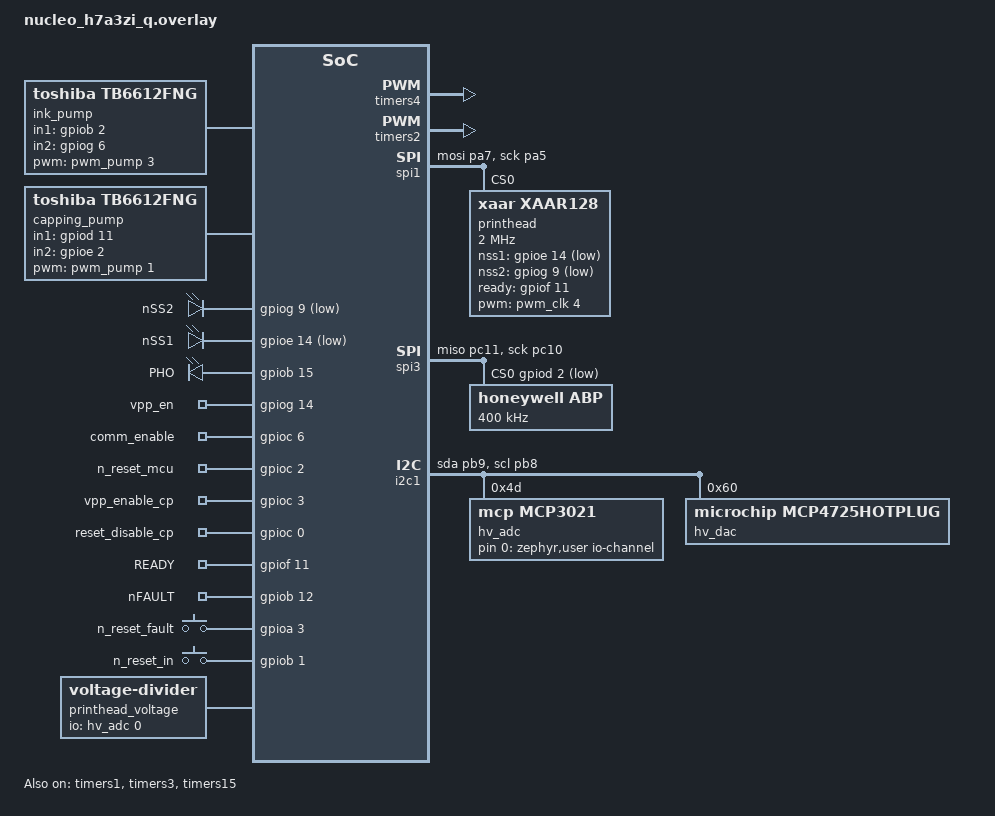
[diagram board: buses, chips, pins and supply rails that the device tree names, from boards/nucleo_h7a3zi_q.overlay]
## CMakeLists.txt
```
#-------------------------------------------------------------------------------
# Zephyr Example Application
#
# Copyright (c) 2021 Nordic Semiconductor ASA
# SPDX-License-Identifier: Apache-2.0

cmake_minimum_required(VERSION 3.13.1)
find_package(Zephyr REQUIRED HINTS $ENV{ZEPHYR_BASE})

project(app LANGUAGES C)

set(PROTOC_OPTIONS "--experimental_allow_proto3_optional")



list(APPEND CMAKE_MODULE_PATH ${ZEPHYR_BASE}/modules/nanopb)
include(nanopb)
zephyr_nanopb_sources(app src/printer_system_state.proto)
zephyr_nanopb_sources(app src/printer_system_state_response.proto)
zephyr_nanopb_sources(app src/printer_request.proto)
zephyr_nanopb_sources(app src/pressure_control.proto)
zephyr_nanopb_sources(app src/print_control.proto)
zephyr_nanopb_sources(app src/waveform_control.proto)

target_sources(app PRIVATE src/main.c)
target_sources(app PRIVATE src/printhead_routines.c)
target_sources(app PRIVATE src/pressure_control.c)
target_sources(app PRIVATE src/pressure_control_algorithm.c)
target_sources(app PRIVATE src/printer_system_smf.c)
target_sources(app PRIVATE src/failure_handling.c)
target_sources(app PRIVATE src/webusb.c)
target_sources(app PRIVATE src/webusb_initialize.c)
target_sources(app PRIVATE src/dropwatcher_light.c)
target_sources(app PRIVATE src/moving_average.c)
target_sources(app PRIVATE src/print_control.c)
target_sources(app PRIVATE src/regulator.c)
include_directories(include)
```

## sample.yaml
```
# This file is provided so that the application can be compiled using Twister,
# the Zephyr testing tool. In this file, multiple combinations can be specified,
# so that you can easily test all of them locally or in CI.
sample:
  description: Inkjet Printer
  name: inkjet-printer
common:
  build_only: true
  integration_platforms:
    - custom_plank
    - nucleo_f302r8
tests:
  app.default: {}
  app.debug:
    extra_overlay_confs:
      - debug.conf
```

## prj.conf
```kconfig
# Copyright (c) 2021 Nordic Semiconductor ASA
# SPDX-License-Identifier: Apache-2.0
#
# This file contains selected Kconfig options for the application.
CONFIG_LOG=y
CONFIG_PRINTER=y
CONFIG_PWM=y
CONFIG_PRINTER_LOG_LEVEL_INF=y
CONFIG_SHELL=y
CONFIG_EVENTS=y
CONFIG_SMF=y
CONFIG_SENSOR=y
CONFIG_MOTOR=y
CONFIG_ADC=y
CONFIG_DAC=y
CONFIG_CBPRINTF_FP_SUPPORT=y
CONFIG_INKJETCONTROL=y
CONFIG_INKJETCONTROL_LOG_LEVEL_INF=y


CONFIG_USB_DEVICE_STACK=y
CONFIG_USB_DEVICE_BOS=y
CONFIG_USB_DEVICE_PRODUCT="Zephyr WebUSB sample"
CONFIG_USB_DEVICE_PID=0x000A
CONFIG_USB_DEVICE_VID=0x2FE3
CONFIG_USB_DEVICE_INITIALIZE_AT_BOOT=n
# CONFIG_USB_DEVICE_LOG_LEVEL_DBG=y

CONFIG_NANOPB=y

CONFIG_SYSTEM_WORKQUEUE_STACK_SIZE=2048
```

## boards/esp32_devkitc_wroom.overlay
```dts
/ {

    ink_pump: ink_pump {
		status = "okay";
		compatible = "toshiba,tb6612fng";
		pwms = <&mcpwm0 0 PWM_HZ(1000) PWM_POLARITY_NORMAL>;
		in1-gpios = <&gpio0 23 GPIO_ACTIVE_HIGH>;
		in2-gpios = <&gpio0 22 GPIO_ACTIVE_HIGH>;
	};
};


&spi2 {
    status = "okay";
    abp: abp@0 {
		status = "okay";
		compatible = "honeywell,abp";
		reg = <0>;
		spi-max-frequency = <400000>;
	};
};

 &pinctrl {
    mcpwm0_default: mcpwm0_default {
      group1 {
        pinmux = <MCPWM0_OUT0A_GPIO2>;
        output-enable;
      };
    };
  };

&mcpwm0 {
    status = "okay";
    prescale = <255>;
    prescale-timer0 = <1>;
    pinctrl-0 = <&mcpwm0_default>;
    pinctrl-names = "default";
};
```

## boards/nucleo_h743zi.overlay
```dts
#define PRINTHEAD_CLOCK_NS PWM_HZ(1000000)
#define MAX_FIRE_FREQUENCY PWM_HZ(4000)

/ {

	pwmclock: pwmclock1 {
		status = "okay";
		compatible = "pwm-clock";
		#clock-cells = <1>;
		pwms = <&pwm_clk 4 PRINTHEAD_CLOCK_NS PWM_POLARITY_INVERTED>;
	};

    ink_pump: ink_pump {
		status = "okay";
		compatible = "toshiba,tb6612fng";
		pwms = <&pwm_pump 3 PWM_HZ(1000) PWM_POLARITY_NORMAL>;
		in1-gpios = <&gpiob 2 GPIO_ACTIVE_HIGH>;
		in2-gpios = <&gpiog 6 GPIO_ACTIVE_HIGH>;
	};

	controlpins: controlpins {
		compatible = "gpio-leds";
		nSS2: nSS2 { //these will be handled in the printhead driver
			gpios = <&gpiog 9 GPIO_ACTIVE_LOW>;
		};
		nSS1: nSS1 {
			gpios = <&gpioe 14 GPIO_ACTIVE_LOW>;
		};
		PHO: PHO {
			gpios = <&gpiob 15 GPIO_ACTIVE_HIGH>;
		};

		//outputs
		vpp_en: vpp_en {
			gpios = <&gpiog 14 GPIO_ACTIVE_HIGH>;
		};
		comm_enable: comm_enable {
			gpios = <&gpioc 6 GPIO_ACTIVE_HIGH>;
		};
		n_reset_mcu: n_reset_mcu {
			gpios = <&gpioc 2 GPIO_ACTIVE_HIGH>;
		};
		vpp_enable_cp: vpp_enable_cp {
			gpios = <&gpioc 3 GPIO_ACTIVE_HIGH>;
		};
		reset_disable_cp: reset_disable_cp {
			gpios = <&gpioc 0 GPIO_ACTIVE_HIGH>;
		};
	};

	monitorpins: monitorpins {
		compatible = "gpio-keys";

		READY: READY {
			gpios = <&gpiof 11 GPIO_ACTIVE_HIGH>;
		};
		nFAULT: nFAULT {
			gpios = <&gpiob 12 GPIO_ACTIVE_HIGH>;
		};

		//inputs
		n_reset_fault: n_reset_fault {
			gpios = <&gpioa 3 GPIO_ACTIVE_HIGH>;
		};
		n_reset_in: n_reset_in {
			gpios = <&gpiob 1 GPIO_ACTIVE_HIGH>;
		};
	};
};


&pll {
	div-m = <1>;
	mul-n = <24>;
	div-p = <2>;
	div-q = <2>;
	div-r = <2>;
	clocks = <&clk_hse>;
	status = "okay";
};

&rcc {
	clocks = <&pll>;
	clock-frequency = <DT_FREQ_M(96)>;
	d1cpre = <1>;
	hpre = <1>;
	d1ppre = <1>;
	d2ppre1 = <2>;
	d2ppre2 = <1>;
	d3ppre = <1>;
};

&timers4 {
	st,prescaler = <0>;

	status = "okay";
	pwm_clk: pwm {
		status = "okay";
		pinctrl-names = "default";
		pinctrl-0 = <&tim4_ch4_pd15>;
	};
};

&timers2 {
	status = "okay";
	st,prescaler = <64>;

	pwm_pump: pwm {
		status = "okay";
		pinctrl-names = "default";
		pinctrl-0 = <&tim2_ch3_pa2>;
	};	
};

&timers1 {
	st,prescaler = <0>;
	status = "okay";

	printer_fire: printer_fire {
		compatible = "st,fire-stm32-combined-pwm";
		status = "okay";
		pinctrl-names = "default";
		pinctrl-0 = <&tim1_ch2_pe11 &tim1_ch3_pe13>;
		pulse12_start = <(PRINTHEAD_CLOCK_NS/4)>;
		pulse34_start = <(PRINTHEAD_CLOCK_NS/4)>;
		pulse12_end = <((PRINTHEAD_CLOCK_NS/4) + PRINTHEAD_CLOCK_NS)>;
		pulse34_end = <(2*PRINTHEAD_CLOCK_NS)>;
		mask_period = <MAX_FIRE_FREQUENCY>;
	};
};

&spi1 {
	status = "okay";
	pinctrl-names = "default";
	pinctrl-0 = <&spi1_mosi_pa7 &spi1_sck_pa5>;
	printhead: printhead@0 {
		compatible = "xaar,xaar128";
		clocks = <&pwmclock 0>;
		reg = <0>;
		spi-max-frequency = <1000000>;
		nss1-gpios = <&gpioe 14 GPIO_ACTIVE_LOW>;
		nss2-gpios = <&gpiog 9 GPIO_ACTIVE_LOW>;
	};
};

&spi3 {
	status = "okay";
	pinctrl-names = "default";
	pinctrl-0 = <&spi3_miso_pc11 &spi3_sck_pc10>;
	cs-gpios = <&gpiod 2 GPIO_ACTIVE_LOW>;
	abp: abp@0 {
		status = "okay";
		compatible = "honeywell,abp";
		reg = <0>;
		spi-max-frequency = <400000>;
	};
};
```

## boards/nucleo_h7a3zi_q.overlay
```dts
#define PRINTHEAD_CLOCK_NS PWM_HZ(1000000)
#define MAX_FIRE_FREQUENCY PWM_HZ(4250)

/ {
	zephyr,user {
		io-channels =  <&hv_adc 0>;
	};

    ink_pump: ink_pump {
		status = "okay";
		compatible = "toshiba,tb6612fng";
		pwms = <&pwm_pump 3 PWM_HZ(1000) PWM_POLARITY_NORMAL>;
		in1-gpios = <&gpiob 2 GPIO_ACTIVE_HIGH>;
		in2-gpios = <&gpiog 6 GPIO_ACTIVE_HIGH>;
	};

	capping_pump: capping_pump {
		status = "okay";
		compatible = "toshiba,tb6612fng";
		pwms = <&pwm_pump 1 PWM_HZ(1000) PWM_POLARITY_NORMAL>;
		in1-gpios = <&gpiod 11 GPIO_ACTIVE_HIGH>;
		in2-gpios = <&gpioe 2 GPIO_ACTIVE_HIGH>;
	};

	controlpins: controlpins {
		compatible = "gpio-leds";
		nSS2: nSS2 { //these will be handled in the printhead driver
			gpios = <&gpiog 9 GPIO_ACTIVE_LOW>;
		};
		nSS1: nSS1 {
			gpios = <&gpioe 14 GPIO_ACTIVE_LOW>;
		};
		PHO: PHO {
			gpios = <&gpiob 15 GPIO_ACTIVE_HIGH>;
		};

		//outputs
		vpp_en: vpp_en {
			gpios = <&gpiog 14 GPIO_ACTIVE_HIGH>;
		};
		comm_enable: comm_enable {
			gpios = <&gpioc 6 GPIO_ACTIVE_HIGH>;
		};
		n_reset_mcu: n_reset_mcu {
			gpios = <&gpioc 2 GPIO_ACTIVE_HIGH>;
		};
		vpp_enable_cp: vpp_enable_cp {
			gpios = <&gpioc 3 GPIO_ACTIVE_HIGH>;
		};
		reset_disable_cp: reset_disable_cp {
			gpios = <&gpioc 0 GPIO_ACTIVE_HIGH>;
		};
	};

	monitorpins: monitorpins {
		compatible = "gpio-keys";

		READY: READY {
			gpios = <&gpiof 11 GPIO_ACTIVE_HIGH>;
		};
		nFAULT: nFAULT {
			gpios = <&gpiob 12 GPIO_ACTIVE_HIGH>;
		};

		//inputs
		n_reset_fault: n_reset_fault {
			gpios = <&gpioa 3 GPIO_ACTIVE_HIGH>;
		};
		n_reset_in: n_reset_in {
			gpios = <&gpiob 1 GPIO_ACTIVE_HIGH>;
		};
	};

    printhead_voltage: printhead_voltage {
    	compatible = "voltage-divider";
    	io-channels = <&hv_adc 0>;
    	output-ohms = <12000>;
    	full-ohms = <(100000 + 12000)>;
    };
};


&pll {
	div-m = <1>;
	mul-n = <24>;
	div-p = <2>;
	div-q = <2>;
	div-r = <2>;
	clocks = <&clk_hse>;
	status = "okay";
};

&rcc {
	clocks = <&pll>;
	clock-frequency = <DT_FREQ_M(96)>;
	d1cpre = <1>;
	hpre = <1>;
	d1ppre = <1>;
	d2ppre1 = <2>;
	d2ppre2 = <1>;
	d3ppre = <1>;
};

&timers4 {
	st,prescaler = <0>;

	status = "okay";
	pwm_clk: pwm {
		status = "okay";
		pinctrl-names = "default";
		pinctrl-0 = <&tim4_ch4_pd15>;
	};
};

&timers2 {
	status = "okay";
	st,prescaler = <64>;

	pwm_pump: pwm {
		status = "okay";
		pinctrl-names = "default";
		pinctrl-0 = <&tim2_ch3_pa2 &tim2_ch1_pa0>;
	};	
};

&timers1 {
	st,prescaler = <0>;
	status = "okay";

	interrupts = <24 1>, <25 1>, <26 0>, <27 1>;

	printer_fire: printer_fire {
		compatible = "st,fire-stm32-combined-pwm";
		status = "okay";
		pinctrl-names = "default";
		pinctrl-0 = <&tim1_ch2_pe11 &tim1_ch3_pe13>;
		pulse12_start = <(PRINTHEAD_CLOCK_NS/4)>;
		pulse34_start = <(PRINTHEAD_CLOCK_NS/4)>;
		pulse12_end = <((PRINTHEAD_CLOCK_NS/4) + PRINTHEAD_CLOCK_NS)>;
		pulse34_end = <(2*PRINTHEAD_CLOCK_NS)>;
		min_mask_period = <MAX_FIRE_FREQUENCY>;
		#printer-fire-cells = <0>;
		encoder_timer = <&timers3>;
		clock_timer = <&timers4>;
		encoder_timer_trigger = <0>; // ITR0 -> timer15
		clock_timer_trigger = <((1<<4)|(2<<4))>; // ITR3 -> timer4
	};
};

&timers3 {
	st,prescaler = <0>; // apb 1
	status = "okay";

	interrupts = <29 1>;

	qdec: qdec {
		compatible = "st,stm32-qdec-linear";
		status = "okay";
		pinctrl-0 = <&tim3_ch1_pb4 &tim3_ch2_pc7>;
		pinctrl-names = "default";
		st,input-polarity-inverted;
		st,input-filter-level = <15>; // f/32, n=8
		st,encoder-mode = <3>;
		encoder-xor-timer = <&timers15>;
		encoder-xor-timer-remap = <((2<<0)|(2<<8))>; // LL_TIM_TIM15_TI1_RMP_TIM3_CH1 | LL_TIM_TIM15_TI2_RMP_TIM3_CH2
	};
};

&timers15 {
	st,prescaler = <0>;
	status = "okay";
};

&spi1 {
	status = "okay";
	pinctrl-names = "default";
	pinctrl-0 = <&spi1_mosi_pa7 &spi1_sck_pa5>;
	printhead: printhead@0 {
		compatible = "xaar,xaar128";
		pwms= <&pwm_clk 4 PRINTHEAD_CLOCK_NS PWM_POLARITY_INVERTED>;
		reg = <0>;
		spi-max-frequency = <2000000>;
		nss1-gpios = <&gpioe 14 GPIO_ACTIVE_LOW>;
		nss2-gpios = <&gpiog 9 GPIO_ACTIVE_LOW>;
		ready-gpios = <&gpiof 11 GPIO_ACTIVE_HIGH>;
		printer-fires = <&printer_fire>;
	};
};

&spi3 {
	status = "okay";
	pinctrl-names = "default";
	pinctrl-0 = <&spi3_miso_pc11 &spi3_sck_pc10>;
	cs-gpios = <&gpiod 2 GPIO_ACTIVE_LOW>;
	abp: abp@0 {
		status = "okay";
		compatible = "honeywell,abp";
		reg = <0>;
		spi-max-frequency = <400000>;
	};
};

&usart3 {
	interrupts = <39 1>;
};

&usbotg_hs {
	interrupts = <77 1>, <74 1>, <75 1>;
};

&exti {
	interrupts = <6 1>, <7 1>, <8 1>, <9 1>,
				     <10 1>, <23 1>, <40 1>;
};

&i2c1 {
	status = "okay";
	pinctrl-names = "default";
	pinctrl-0 = <&i2c1_sda_pb9 &i2c1_scl_pb8>;
	hv_adc: adc@4d {
		status = "okay";
		compatible = "mcp,mcp3021";

		#io-channel-cells = <1>;
		#address-cells = <1>;
		#size-cells = <0>;
		
		
		reg = <0x4d>;

		ref-internal-mv = <5000>;

		channel@0 {
			reg = <0>;
			zephyr,gain = "ADC_GAIN_1";
			zephyr,reference = "ADC_REF_INTERNAL";
			zephyr,acquisition-time = <ADC_ACQ_TIME_DEFAULT>;
			zephyr,resolution = <10>;
		};
	};

	hv_dac: dac@60 {
		status = "okay";
		compatible = "microchip,mcp4725hotplug";
		
		#io-channel-cells = <1>;
		#address-cells = <1>;
		#size-cells = <0>;

		reg = <0x60>;

	};
};
```

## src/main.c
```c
#include <zephyr/kernel.h>
#include <zephyr/drivers/printer.h>
#include <zephyr/drivers/printer_fire.h>
#include <app_version.h>
#include <zephyr/kernel.h>
#include <zephyr/device.h>
#include <zephyr/drivers/gpio.h>
#include <zephyr/sys/util.h>
#include <zephyr/sys/printk.h>
#include <inttypes.h>
#include <zephyr/logging/log.h>
#include <zephyr/shell/shell.h>
#include <zephyr/console/console.h>
#include <stdlib.h>
#include <zephyr/drivers/sensor.h>
#include <zephyr/drivers/motor.h>
#include <zephyr/drivers/pwm.h>

#include "pressure_control.h"
#include "printhead_routines.h"
#include "printer_system_smf.h"
#include "failure_handling.h"
#include "print_control.h"
#include "regulator.h"

LOG_MODULE_REGISTER(main, CONFIG_APP_LOG_LEVEL);
#define SW0_NODE DT_ALIAS(sw0)
#if !DT_NODE_HAS_STATUS(SW0_NODE, okay)
#error "Unsupported board: sw0 devicetree alias is not defined"
#endif

static const struct gpio_dt_spec button = GPIO_DT_SPEC_GET_OR(SW0_NODE, gpios,
															  {0});
static struct gpio_callback button_cb_data;

static const struct gpio_dt_spec vpp_en = GPIO_DT_SPEC_GET(DT_NODELABEL(vpp_en), gpios);
static const struct gpio_dt_spec comm_enable = GPIO_DT_SPEC_GET(DT_NODELABEL(comm_enable), gpios);
static const struct gpio_dt_spec vpp_enable_cp = GPIO_DT_SPEC_GET(DT_NODELABEL(vpp_enable_cp), gpios);

static const struct gpio_dt_spec n_reset_fault = GPIO_DT_SPEC_GET(DT_NODELABEL(n_reset_fault), gpios);
static const struct gpio_dt_spec n_reset_in = GPIO_DT_SPEC_GET(DT_NODELABEL(n_reset_in), gpios);

static struct gpio_dt_spec nSS2 = GPIO_DT_SPEC_GET(DT_NODELABEL(nss2), gpios);
static struct gpio_dt_spec nSS1 = GPIO_DT_SPEC_GET(DT_NODELABEL(nss1), gpios);
static struct gpio_dt_spec PHO = GPIO_DT_SPEC_GET(DT_NODELABEL(pho), gpios);

static struct gpio_dt_spec nFAULT = GPIO_DT_SPEC_GET(DT_NODELABEL(nfault), gpios);
static struct gpio_dt_spec READY = GPIO_DT_SPEC_GET(DT_NODELABEL(ready), gpios);

static struct gpio_callback READY_cb_data;

void encoder_debug_timer_handler(struct k_timer *timer)
{
	const struct device *const dev = DEVICE_DT_GET(DT_NODELABEL(qdec));
	if (!device_is_ready(dev))
	{
		printk("Qdec device is not ready\n");
		return;
	}
	struct sensor_value val;
	int rc = sensor_sample_fetch(dev);
	rc = sensor_channel_get(dev, SENSOR_CHAN_POS_DX, &val);
	if (rc != 0)
	{
		printk("Failed to get data (%d)\n", rc);
		return;
	}
	printk("Encoder value: %d\n", val.val1);
}

void pressure_debug_timer_handler(struct k_timer *timer)
{
	double pressure = pressure_control_get_pressure();
	printk("Pressure: %f mbar\n", pressure);
}
static int fire_count = 0;
static int drop_count = 100;

void print_fire_timer_handler(struct k_timer *timer);

K_TIMER_DEFINE(pressure_debug_timer, pressure_debug_timer_handler, NULL);

K_TIMER_DEFINE(print_fire_timer, print_fire_timer_handler, NULL);

K_TIMER_DEFINE(encoder_debug_timer, encoder_debug_timer_handler, NULL);

static uint32_t pattern[4] = {0, 0, 0, 1};

static void advance_pattern()
{
	bool filling = (pattern[3] & 0x80000000) == 0;
	for (int i = 3; i >= 0; i--)
	{
		pattern[i] = (pattern[i] << 1);
		if (i > 0 && (pattern[i - 1] & 0x80000000))
		{
			pattern[i] |= 1;
		}
	}
	if (pattern[3] & 0x80000000)
	{
		pattern[0] |= 1;
	}
	// if (filling)
	// {
	// 	pattern[0] |= 1;
	// }
}

void print_fire_timer_handler(struct k_timer *timer)
{
	if (gpio_pin_get_dt(&READY) == 1)
	{
		// if (fire_count % 30 == 0)
		// {
		// 	advance_pattern();
		// }
		const struct device *printhead = DEVICE_DT_GET(DT_NODELABEL(printhead));
		// printer_set_pixels(printhead, pattern);
		request_printhead_fire();
	}
	fire_count++;
	if (fire_count > drop_count)
	{
		k_timer_stop(&print_fire_timer);
		fire_count = 0;
	}
}

K_EVENT_DEFINE(btn_event);

void button_pressed(const struct device *dev, struct gpio_callback *cb,
					uint32_t pins)
{
	failure_handling_set_error_state(ERROR_USER_ABORT);
}

void READY_int_handler(const struct device *dev, struct gpio_callback *cb,
					   uint32_t pins)
{
	LOG_INF("READY changed to %d", gpio_pin_get_dt(&READY));
}

static int printhead_io_init()
{
	int ret;
	if (!gpio_is_ready_dt(&nSS2))
	{
		LOG_ERR("Error: nSS2 device %s is not ready\n",
				nSS2.port->name);
		return ENODEV;
	}
	ret = gpio_pin_configure_dt(&nSS2, GPIO_OUTPUT_INACTIVE);
	if (ret != 0)
	{
		LOG_ERR("Error %d: failed to configure %s pin %d\n",
				ret, nSS2.port->name, nSS2.pin);
		return ret;
	}
	if (!gpio_is_ready_dt(&nSS1))
	{
		LOG_ERR("Error: nSS1 device %s is not ready\n",
				nSS1.port->name);
		return ENODEV;
	}
	ret = gpio_pin_configure_dt(&nSS1, GPIO_OUTPUT_INACTIVE);
	if (ret != 0)
	{
		LOG_ERR("Error %d: failed to configure %s pin %d\n",
				ret, nSS1.port->name, nSS1.pin);
		return ret;
	}
	if (!gpio_is_ready_dt(&PHO))
	{
		LOG_ERR("Error: PHO device %s is not ready\n",
				PHO.port->name);
		return ENODEV;
	}
	ret = gpio_pin_configure_dt(&PHO, GPIO_OUTPUT_INACTIVE);
	if (ret != 0)
	{
		LOG_ERR("Error %d: failed to configure %s pin %d\n",
				ret, PHO.port->name, PHO.pin);
		return ret;
	}
	if (!gpio_is_ready_dt(&READY))
	{
		LOG_ERR("Error: READY device %s is not ready\n",
				READY.port->name);
		return ENODEV;
	}
	ret = gpio_pin_configure_dt(&READY, GPIO_INPUT);
	if (ret != 0)
	{
		LOG_ERR("Error %d: failed to configure %s pin %d\n",
				ret, READY.port->name, READY.pin);
		return ret;
	}
	ret = gpio_pin_interrupt_configure_dt(&READY,
										  GPIO_INT_EDGE_BOTH);
	if (ret != 0)
	{
		LOG_ERR("Error %d: failed to configure interrupt on %s pin %d\n",
				ret, READY.port->name, READY.pin);
		return ret;
	}
	gpio_init_callback(&READY_cb_data, READY_int_handler, BIT(READY.pin));
	ret = gpio_add_callback(READY.port, &READY_cb_data);
	if (ret != 0)
	{
		LOG_ERR("Error %d: failed to add callback on %s pin %d\n",
				ret, READY.port->name, READY.pin);
		return ret;
	}
	return 0;
}

int initialize_io()
{
	int ret;
	ret = printhead_io_init();
	if (ret != 0)
	{
		return ret;
	}
	return 0;
}

static int shell_wait(const struct shell *sh)
{
	int32_t events;
	shell_print(sh, "Press button to continue.");
	k_event_clear(&btn_event, 0x1);
	events = k_event_wait_all(&btn_event, 0x1, false, K_SECONDS(20));
	if (events == 0)
	{
		shell_print(sh, "Timeout");
		return ETIMEDOUT;
	}
	return 0;
}

static int cmd_test_hv_supply(const struct shell *sh, size_t argc, char **argv)
{
	ARG_UNUSED(argc);
	ARG_UNUSED(argv);

	shell_print(sh, "Disconnect HV supply, discharge capacitor, confirm 0V on printhead connector VPPH and VPPL.");
	if (shell_wait(sh) == ETIMEDOUT)
	{
		return ETIMEDOUT;
	}
	shell_print(sh, "Connect HV supply, confirm 0V on printhead connector VPPH and VPPL.");
	if (shell_wait(sh) == ETIMEDOUT)
	{
		return ETIMEDOUT;
	}
	gpio_pin_set_dt(&vpp_en, 1);
	shell_print(sh, "Confirm again 0V on VPPH and VPPL.");
	if (shell_wait(sh) == ETIMEDOUT)
	{
		return ETIMEDOUT;
	}
	gpio_pin_set_dt(&vpp_enable_cp, 1);
	k_sleep(K_MSEC(1));
	gpio_pin_set_dt(&vpp_enable_cp, 0);
	shell_print(sh, "Confirm VPPH and VPPL active.");
	if (shell_wait(sh) == ETIMEDOUT)
	{
		return ETIMEDOUT;
	}
	gpio_pin_set_dt(&vpp_en, 0);
	shell_print(sh, "Confirm again 0V on VPPH and VPPL.");
	if (shell_wait(sh) == ETIMEDOUT)
	{
		return ETIMEDOUT;
	}
	shell_print(sh, "done");
	return 0;
}

static int cmd_test_printhead_io(const struct shell *sh, size_t argc, char **argv)
{
	ARG_UNUSED(argc);
	ARG_UNUSED(argv);

	gpio_pin_set_dt(&nSS2, 1);
	gpio_pin_set_dt(&nSS1, 1);
	gpio_pin_set_dt(&PHO, 0);
	gpio_pin_set_dt(&comm_enable, 1);
	shell_print(sh, "Connect nSS2 to READY");
	if (shell_wait(sh) == ETIMEDOUT)
	{
		return ETIMEDOUT;
	}
	if (gpio_pin_get_dt(&READY) != 0)
	{
		shell_print(sh, "READY is not low");
		return EINVAL;
	}
	gpio_pin_set_dt(&nSS2, 0);
	k_sleep(K_MSEC(1));
	if (gpio_pin_get_dt(&READY) != 1)
	{
		shell_print(sh, "READY is not high");
		return EINVAL;
	}
	gpio_pin_set_dt(&nSS2, 1);
	shell_print(sh, "Connect nSS1 to READY");
	if (shell_wait(sh) == ETIMEDOUT)
	{
		return ETIMEDOUT;
	}
	if (gpio_pin_get_dt(&READY) != 0)
	{
		shell_print(sh, "READY is not low");
		return EINVAL;
	}
	gpio_pin_set_dt(&nSS1, 0);
	k_sleep(K_MSEC(1));
	if (gpio_pin_get_dt(&READY) != 1)
	{
		shell_print(sh, "READY is not high");
		return EINVAL;
	}
	gpio_pin_set_dt(&nSS1, 1);
	shell_print(sh, "Connect PHO to nFAULT");
	if (shell_wait(sh) == ETIMEDOUT)
	{
		return ETIMEDOUT;
	}
	if (gpio_pin_get_dt(&nFAULT) != 0)
	{
		shell_print(sh, "nFAULT is not low");
		return EINVAL;
	}
	gpio_pin_set_dt(&PHO, 1);
	k_sleep(K_MSEC(1));
	if (gpio_pin_get_dt(&nFAULT) != 1)
	{
		shell_print(sh, "nFAULT is not high");
		return EINVAL;
	}
	gpio_pin_set_dt(&PHO, 0);
	shell_print(sh, "done");
	return 0;
}

static int cmd_test_other_io(const struct shell *sh, size_t argc, char **argv)
{
	ARG_UNUSED(argc);
	ARG_UNUSED(argv);
	gpio_pin_set_dt(&comm_enable, 0);
	shell_print(sh, "Connect COMM_ENABLE to nRESET_FAULT");
	if (shell_wait(sh) == ETIMEDOUT)
	{
		return ETIMEDOUT;
	}
	if (gpio_pin_get_dt(&n_reset_fault) != 0)
	{
		shell_print(sh, "nRESET_FAULT is not low");
		return EINVAL;
	}
	gpio_pin_set_dt(&comm_enable, 1);
	k_sleep(K_MSEC(1));
	if (gpio_pin_get_dt(&n_reset_fault) != 1)
	{
		shell_print(sh, "nRESET_FAULT is not high");
		return EINVAL;
	}
	gpio_pin_set_dt(&comm_enable, 0);
	shell_print(sh, "Connect COMM_ENABLE to nRESET_IN");
	if (shell_wait(sh) == ETIMEDOUT)
	{
		return ETIMEDOUT;
	}
	if (gpio_pin_get_dt(&n_reset_in) != 0)
	{
		shell_print(sh, "nRESET_IN is not low");
		return EINVAL;
	}
	gpio_pin_set_dt(&comm_enable, 1);
	k_sleep(K_MSEC(1));
	if (gpio_pin_get_dt(&n_reset_in) != 1)
	{
		shell_print(sh, "nRESET_IN is not high");
		return EINVAL;
	}
	gpio_pin_set_dt(&comm_enable, 0);
	shell_print(sh, "done");
	return 0;
}

static int cmd_set_pixels(const struct shell *sh, size_t argc, char **argv)
{
	if (argc != 5)
	{
		shell_print(sh, "Usage: set_pixels <pixels1> <pixels2> <pixels3> <pixels4>");
		return EINVAL;
	}
	uint32_t pixels[4] = {(uint32_t)strtoll(argv[1], NULL, 16), (uint32_t)strtoll(argv[2], NULL, 16), (uint32_t)strtoll(argv[3], NULL, 16), (uint32_t)strtoll(argv[4], NULL, 16)};
	shell_print(sh, "Setting pixels to %d %d %d %d", pixels[0], pixels[1], pixels[2], pixels[3]);
	k_sleep(K_SECONDS(1));
	const struct device *printhead;
	printhead = DEVICE_DT_GET(DT_NODELABEL(printhead));

	return printer_set_pixels(printhead, pixels);
}

static int cmd_comm_enable(const struct shell *sh, size_t argc, char **argv)
{
	if (argc != 2)
	{
		shell_print(sh, "Usage: comm_enable <0|1>");
		return EINVAL;
	}
	int value = atoi(argv[1]);
	if (value != 0 && value != 1)
	{
		shell_print(sh, "Usage: comm_enable <0|1>");
		return EINVAL;
	}
	gpio_pin_set_dt(&comm_enable, value);
	return 0;
}

static int cmd_pressure_control_enable(const struct shell *sh, size_t argc, char **argv, void *data)
{
	ARG_UNUSED(argc);
	ARG_UNUSED(argv);
	bool enable = (bool)data;
	if (enable)
	{
		pressure_control_enable();
	}
	else
	{
		pressure_control_disable();
	}
	return 0;
}

SHELL_SUBCMD_DICT_SET_CREATE(pressure_control_enable_cmds, cmd_pressure_control_enable,
							 (enable, true, "enable"), (disable, false, "disable"));

static int cmd_pressure_control_print_pressure(const struct shell *sh, size_t argc, char **argv, void *data)
{
	ARG_UNUSED(argc);
	ARG_UNUSED(argv);
	bool enable = (bool)data;
	if (enable)
	{
		k_timer_start(&pressure_debug_timer, K_SECONDS(1), K_SECONDS(1));
	}
	else
	{
		k_timer_stop(&pressure_debug_timer);
	}
	return 0;
}

SHELL_SUBCMD_DICT_SET_CREATE(pressure_control_print_pressure_cmds, cmd_pressure_control_print_pressure,
							 (enable, true, "enable"), (disable, false, "disable"));

static int cmd_encoder_print(const struct shell *sh, size_t argc, char **argv, void *data)
{
	ARG_UNUSED(argc);
	ARG_UNUSED(argv);
	bool enable = (bool)data;
	if (enable)
	{
		k_timer_start(&encoder_debug_timer, K_SECONDS(1), K_SECONDS(1));
	}
	else
	{
		k_timer_stop(&encoder_debug_timer);
	}
	return 0;
}

SHELL_SUBCMD_DICT_SET_CREATE(encoder_print_cmds, cmd_encoder_print,
							 (enable, true, "enable"), (disable, false, "disable"));

static int cmd_pressure_control_calibrate_zero_pressure(const struct shell *sh, size_t argc, char **argv)
{
	ARG_UNUSED(argc);
	ARG_UNUSED(argv);
	return calibrate_zero_pressure();
}

static int cmd_test_pump(const struct shell *sh, size_t argc, char **argv)
{
	ARG_UNUSED(argc);
	ARG_UNUSED(argv);
	if (argc != 4)
	{
		goto print_pump_usage;
	}
	const struct device *pump;
	char *pump_name_capping = "capping";
	char *pump_name_ink = "ink";
	char *pump_name;
	if (strcmp(argv[1], "ink") == 0)
	{
		pump = DEVICE_DT_GET(DT_NODELABEL(ink_pump));
		pump_name = pump_name_ink;
	}
	else if (strcmp(argv[1], "capping") == 0)
	{
		pump = DEVICE_DT_GET(DT_NODELABEL(capping_pump));
		pump_name = pump_name_capping;
	}
	else
	{
		goto print_pump_usage;
	}
	motor_action_t action;
	if (strcmp(argv[2], "cw") == 0)
	{
		action = MOTOR_ACTION_CW;
	}
	else if (strcmp(argv[2], "ccw") == 0)
	{
		action = MOTOR_ACTION_CCW;
	}
	else if (strcmp(argv[2], "brake") == 0)
	{
		action = MOTOR_ACTION_SHORT_BRAKE;
	}
	else if (strcmp(argv[2], "stop") == 0)
	{
		action = MOTOR_ACTION_STOP;
	}
	else
	{
		goto print_pump_usage;
	}
	float speed = atof(argv[3]);
	if (!device_is_ready(pump))
	{
		LOG_ERR("Pump not ready");
		return -ENODEV;
	}
	shell_print(sh, "Setting pump %s to %d at %f", pump_name, action, (double)speed);
	motor_set_action(pump, action, speed);
	return 0;
print_pump_usage:
	shell_print(sh, "Usage: test_pump <ink|capping> <cw|ccw|brake|stop> <pwm>");
	return -EINVAL;
}

static int cmd_system_state(const struct shell *sh, size_t argc, char **argv, void *data)
{
	switch ((int)data)
	{
	case 0:
		k_timer_stop(&print_fire_timer);
		go_to_idle();
		break;
	case 1:
		go_to_dropwatcher();
		break;
	case 2:
		go_to_keep_alive();
	default:
		break;
	}
	return 0;
}

SHELL_SUBCMD_DICT_SET_CREATE(system_state_cmds, cmd_system_state,
							 (idle, 0, "idle"), (dropwatcher, 1, "dropwatcher"), (keepalive, 2, "keepalive"));

static int cmd_fire(const struct shell *sh, size_t argc, char **argv)
{
	if (argc != 3)
	{
		shell_print(sh, "Usage: fire <ms> <drop_count>");
		return EINVAL;
	}
	fire_count = 0;
	drop_count = atoi(argv[2]);
	int interval_us = atoi(argv[1]);
	const struct device *printhead = DEVICE_DT_GET(DT_NODELABEL(printhead));
	// uint32_t pixels[4] = {0xFFFFFFFF, 0xFFFFFFFF, 0xFFFFFFFF, 0xFFFFFFFF};
	// printer_set_pixels(printhead, pixels);
	k_timer_start(&print_fire_timer, K_USEC(interval_us), K_USEC(interval_us));
	return 0;
}

static void cmd_test_fire(const struct shell *sh, size_t argc, char **argv)
{
	ARG_UNUSED(argc);
	ARG_UNUSED(argv);
	const struct device *dev = DEVICE_DT_GET(DT_NODELABEL(printer_fire));
	// if (gpio_pin_get_dt(&comm_enable) != 0)
	// {
	// 	shell_print(sh, "COMM_ENABLE must be low");
	// 	return;
	// }
	printer_fire_request_fire(dev, 1000);
}

static void cmd_enable_printhead_clock(const struct shell *sh, size_t argc, char **argv)
{
	ARG_UNUSED(argc);
	ARG_UNUSED(argv);
	const struct device *printhead = DEVICE_DT_GET(DT_NODELABEL(printhead));
	printer_clock_enable(printhead, PWM_HZ(1000000));
}

static int cmd_print_control_set_mode(const struct shell *sh, size_t argc, char **argv, void *data)
{
	ARG_UNUSED(argc);
	ARG_UNUSED(argv);
	uint32_t mode = (uint32_t)data;
	if (mode == 1)
	{
		print_control_start_manual_fire_mode();
	}
	else if (mode == 2)
	{
		print_control_encoder_mode_settings_t init = {
			.sequential_fires = 1,
			.fire_every_ticks = 1,
			.lines_to_print = 1000,
			.print_first_line_after_encoder_tick = 250};
		print_control_start_encoder_mode(&init);
	}
	else
	{
		shell_print(sh, "Invalid mode");
	}
	return 0;
}

static int cmd_regulator_get_voltage(const struct shell *sh, size_t argc, char **argv)
{
	ARG_UNUSED(argc);
	ARG_UNUSED(argv);
	uint32_t voltage;
	bool read = regulator_get_voltage(&voltage);
	if (!read)
	{
		shell_print(sh, "Failed to read voltage");
		return -EIO;
	}
	else
	{
		shell_print(sh, "Voltage: %d", voltage);
	}
	return 0;
}

static int cmd_regulator_set_voltage(const struct shell *sh, size_t argc, char **argv)
{
	if (argc != 2)
	{
		shell_print(sh, "Usage: regulator_set_voltage <voltage in mv>");
		return EINVAL;
	}
	double voltage = atof(argv[1]);
	int ret = regulator_set_voltage(voltage);
	if (ret != 0)
	{
		shell_print(sh, "Failed to set voltage");
	}
	return ret;
}

SHELL_SUBCMD_DICT_SET_CREATE(print_control_set_mode_cmds, cmd_print_control_set_mode,
							 (manual, 1, "manual"), (encoder, 2, "encoder"));

SHELL_STATIC_SUBCMD_SET_CREATE(sub_test,
							   SHELL_CMD(hv_supply, NULL, "Test HV supply", cmd_test_hv_supply),
							   SHELL_CMD(printhead_io, NULL, "Test printhead IO", cmd_test_printhead_io),
							   SHELL_CMD(other_io, NULL, "Test other IO", cmd_test_other_io),
							   SHELL_CMD(set_pixels, NULL, "Set pixels", cmd_set_pixels),
							   SHELL_CMD(comm_enable, NULL, "Set COMM_ENABLE", cmd_comm_enable),
							   SHELL_CMD(pressure_control_enable, &pressure_control_enable_cmds, "Enable/disable pressure control", NULL),
							   SHELL_CMD(pressure_control_print_pressure, &pressure_control_print_pressure_cmds, "Print pressure", NULL),
							   SHELL_CMD(encoder_print, &encoder_print_cmds, "Print encoder", NULL),
							   SHELL_CMD(print_control_set_mode, &print_control_set_mode_cmds, "Set print control mode", NULL),
							   SHELL_CMD(pressure_control_calibrate_zero_pressure, NULL, "Calibrate zero pressure", cmd_pressure_control_calibrate_zero_pressure),
							   SHELL_CMD(pump, NULL, "Test pump", cmd_test_pump),
							   SHELL_CMD(system_state, &system_state_cmds, "Set system state", cmd_system_state),
							   SHELL_CMD(fire, NULL, "Fire printhead", cmd_fire),
							   SHELL_CMD(test_fire, NULL, "Test fire", cmd_test_fire),
							   SHELL_CMD(enable_printhead_clock, NULL, "Enable printhead clock", cmd_enable_printhead_clock),
							   SHELL_CMD(regulator_get_voltage, NULL, "Get regulator voltage", cmd_regulator_get_voltage),
							   SHELL_CMD(regulator_set_voltage, NULL, "Set regulator voltage", cmd_regulator_set_voltage),
							   SHELL_SUBCMD_SET_END);
SHELL_CMD_REGISTER(test, &sub_test, "Test commands", NULL);

static void pressure_control_error()
{
	failure_handling_set_error_state(ERROR_PRESSURE_CONTROL);
}

static void failure_callback()
{
	printhead_routines_go_to_safe_state();
	pressure_control_go_to_safe_state();
	printer_system_smf_go_to_safe_state();
	print_control_go_to_safe_state();
}

static void printhead_routines_error()
{
	failure_handling_set_error_state(ERROR_PRINTHEAD_RESET);
}

static void printhead_control_error(uint32_t errors)
{
	failure_handling_set_error_state(errors);
}

int main(void)
{
	int ret;
	ret = initialize_io();
	if (ret != 0)
	{
		return ret;
	}

	if (!gpio_is_ready_dt(&button))
	{
		printk("Error: button device %s is not ready\n",
			   button.port->name);
		return 0;
	}

	ret = gpio_pin_configure_dt(&button, GPIO_INPUT);
	if (ret != 0)
	{
		printk("Error %d: failed to configure %s pin %d\n",
			   ret, button.port->name, button.pin);
		return 0;
	}

	ret = gpio_pin_interrupt_configure_dt(&button,
										  GPIO_INT_EDGE_TO_ACTIVE);
	if (ret != 0)
	{
		printk("Error %d: failed to configure interrupt on %s pin %d\n",
			   ret, button.port->name, button.pin);
		return 0;
	}

	gpio_init_callback(&button_cb_data, button_pressed, BIT(button.pin));
	gpio_add_callback(button.port, &button_cb_data);
	printk("Set up button at %s pin %d\n", button.port->name, button.pin);

	printk("Zephyr Example Application %s\n", APP_VERSION_STRING);
	const struct device *printhead;

	printhead = DEVICE_DT_GET(DT_NODELABEL(printhead));

	if (!device_is_ready(printhead))
	{
		LOG_ERR("Printhead not ready");
		return 0;
	}

	pressure_control_init_t pressure_control_init = {
		.error_callback = pressure_control_error};
	ret = pressure_control_initialize(&pressure_control_init);
	if (ret != 0)
	{
		LOG_ERR("Pressure control initialization failed with error %d", ret);
		return ret;
	}

	printhead_routines_init_t printhead_routines_init = {
		.error_callback = printhead_routines_error};
	ret = printhead_routines_initialize(&printhead_routines_init);
	if (ret != 0)
	{
		LOG_ERR("Printhead routines initialization failed with error %d", ret);
		return ret;
	}

	ret = regulator_initialize();
	if (ret != 0)
	{
		LOG_ERR("Regulator initialization failed with error %d", ret);
		return ret;
	}

	failure_handling_init_t failure_handling_init = {
		.failure_callback = failure_callback};
	ret = failure_handling_initialize(&failure_handling_init);
	if (ret != 0)
	{
		LOG_ERR("Failure handling initialization failed with error %d", ret);
		return ret;
	}

	print_control_init_t print_control_init = {
		.error_callback = printhead_control_error};
	ret = print_control_initialize(&print_control_init);
	if (ret != 0)
	{
		LOG_ERR("Print control initialization failed with error %d", ret);
		return ret;
	}

	ret = printer_system_smf();
	if (ret != 0)
	{
		LOG_ERR("Printer system state machine terminated with error %d", ret);
		return ret;
	}
	return 0;
}
```

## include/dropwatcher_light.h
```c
#ifndef DROPWATCHER_LIGHT_H
#define DROPWATCHER_LIGHT_H

#include <stdint.h>

int set_light_timing(uint32_t delay, uint32_t on_time);

#endif /* DROPWATCHER_LIGHT_H */
```

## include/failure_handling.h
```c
#ifndef FAILURE_HANDLING_H
#define FAILURE_HANDLING_H

#include <stdbool.h>
#include <stdint.h>

#define ERROR_PRESSURE_CONTROL (1<<0)
#define ERROR_PRINTHEAD_RESET (1<<1)
#define ERROR_USER_ABORT (1<<2)
#define ERROR_PRINTHEAD_COMMUNICATION (1<<3)
#define ERROR_PRINTHEAD_FIRE (1<<4)
#define ERROR_LOAD_NOT_FINISHED (1<<5)
#define ERROR_PRINTHEAD_READY (1<<6)

typedef void (*failure_callback_t)(void);

typedef struct {
    failure_callback_t failure_callback;
} failure_handling_init_t;

int failure_handling_initialize(failure_handling_init_t *init);

bool failure_handling_is_in_error_state(void);

uint32_t failure_handling_get_error_state(void);

void failure_handling_set_error_state(uint32_t error);

#endif // FAILURE_HANDLING_H
```

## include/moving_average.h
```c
#ifndef MOVING_AVERAGE_H
#define MOVING_AVERAGE_H

#include <stdint.h>

#define MOVING_AVERAGE_SIZE (8)

typedef struct
{
    uint8_t count;
    uint8_t index;
    float sum;
    float data[MOVING_AVERAGE_SIZE];
    float avg;
} moving_average_t;


void moving_average_init(moving_average_t *moving_average);
void moving_average_add(moving_average_t *moving_average, float data);

#endif
```

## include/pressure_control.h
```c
#ifndef PRESSURE_CONTROL_H
#define PRESSURE_CONTROL_H

#ifdef __cplusplus
extern "C"
{
#endif

#include <stdbool.h>
#include <zephyr/kernel.h>
#include "pressure_control_algorithm.h"

    typedef void (*pressure_control_error_callback_t)(void);

    typedef struct
    {
        pressure_control_error_callback_t error_callback;
    } pressure_control_init_t;

    typedef struct
    {
        float pressure;
        bool enabled;
        bool done;
        pressure_control_algorithm_init_t algorithm[NUM_PUMPS];
    } pressure_control_info_t;

    int pressure_control_initialize(pressure_control_init_t *init);

    int calibrate_zero_pressure(void);

    void pressure_control_enable();

    void pressure_control_update_parameters(int pump_idx, pressure_control_algorithm_init_t *init);

    void pressure_control_disable();

    double pressure_control_get_pressure(void);

    void pressure_control_get_info(pressure_control_info_t *info);

    int pressure_control_wait_for_done(k_timeout_t timeout);

    void pressure_control_go_to_safe_state();

#ifdef __cplusplus
}
#endif

#endif // PRESSURE_CONTROL_H
```

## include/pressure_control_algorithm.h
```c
#ifndef PRESSURE_CONTROL_ALGORITHM_H
#define PRESSURE_CONTROL_ALGORITHM_H

#include <stdbool.h>
#include <stdint.h>
#include <zephyr/drivers/motor.h>

typedef enum {
	PRESSURE_CONTROL_ALGORITHM_NONE,
	PRESSURE_CONTROL_ALGORITHM_TARGET_PRESSURE,
	PRESSURE_CONTROL_ALGORITHM_FEED_WITH_LIMIT
} pressure_control_algorithm_t;

typedef enum {
	PRESSURE_DIRECTION_VACUUM,
	PRESSURE_DIRECTION_PRESSURE
} pressure_direction_t;

typedef struct {
	motor_action_t action;
	float pwm;
} pressure_control_algorithm_motor_result_t;

#define PRESSURE_CONTROL_INK_PUMP_IDX (0)
#define PRESSURE_CONTROL_CAPPING_PUMP_IDX (1)

#define NUM_PUMPS (2)

typedef struct {
	pressure_control_algorithm_t algorithm;
	pressure_direction_t direction;
	float target_pressure;
	float max_pressure_limit;
	float min_pressure_limit;
	float feed_pwm;
	float feed_time;
} pressure_control_algorithm_init_t;

typedef struct {
	pressure_control_algorithm_init_t algorithm[NUM_PUMPS];
	bool initial_run;
	bool parameter_change;
	float current_pressure;
    float elapsed_time_seconds;
} pressure_control_algorithm_params_t;



typedef struct {
	pressure_control_algorithm_motor_result_t motor_result[NUM_PUMPS];
    bool done;
    bool failure_detected;
} pressure_control_result_t;

void pressure_control_algorithm(const pressure_control_algorithm_params_t *params, pressure_control_result_t *result);

#endif // PRESSURE_CONTROL_ALGORITHM_H
```

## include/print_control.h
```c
#ifndef PRINT_CONTROL_H
#define PRINT_CONTROL_H

#include <stdint.h>

typedef void (*print_control_error_callback_t)(uint32_t);

typedef struct {
    print_control_error_callback_t error_callback;
} print_control_init_t;

typedef struct
{
    uint32_t sequential_fires;
    uint32_t fire_every_ticks;
    uint32_t print_first_line_after_encoder_tick;
    uint32_t lines_to_print;
    bool start_paused;
} print_control_encoder_mode_settings_t;

typedef enum
{
    ENCODER_MODE_OFF,
    ENCODER_MODE_ON,
    ENCODER_MODE_PAUSED
} encoder_mode_t;

typedef struct {
    print_control_encoder_mode_settings_t encoder_mode_settings;
    int32_t encoder_value;
    int32_t expected_encoder_value;
    int32_t last_printed_line;
    uint32_t lost_lines_count;
    uint32_t printed_lines;
    uint32_t lost_lines_by_slow_data;
    bool nozzle_priming_active;
    encoder_mode_t encoder_mode;
} print_control_info_t;
 
int print_control_start_encoder_mode(print_control_encoder_mode_settings_t *init);
int print_control_start_manual_fire_mode();
void print_control_pause_encoder_mode();
void print_control_resume_encoder_mode();
int print_control_request_fire(uint32_t count);
void print_control_set_encoder_position(int32_t value);
void print_control_disable();
void print_control_set_print_memory(uint32_t offset, uint32_t *data, uint32_t length);
int print_control_initialize(print_control_init_t *init);
void print_control_get_info(print_control_info_t *info);
void print_control_go_to_safe_state();
int print_control_nozzle_priming();

#endif
```

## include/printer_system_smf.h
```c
#ifndef PRINTER_SYSTEM_SMF_H
#define PRINTER_SYSTEM_SMF_H

#include "print_control.h"

enum printer_system_smf_state
{
    PRINTER_SYSTEM_STARTUP,
    PRINTER_SYSTEM_IDLE,
    PRINTER_SYSTEM_ERROR,
    PRINTER_SYSTEM_DROPWATCHER,
    PRINTER_SYSTEM_PRINT,
    PRINTER_SYSTEM_KEEP_ALIVE
};

typedef struct
{
    uint32_t voltage;
    uint32_t clock_period_ns;
} waveform_settings_t;

int printer_system_smf();

void printer_system_smf_go_to_safe_state();
void go_to_dropwatcher();
void go_to_idle();
void go_to_print();
void go_to_keep_alive();

void request_printhead_fire();

void request_set_nozzle_data(uint32_t *data);

void request_change_encoder_mode_settings(print_control_encoder_mode_settings_t *settings);

void request_prime_nozzles();

void request_change_encoder_mode(bool paused);

void request_set_waveform_settings(waveform_settings_t *settings);

enum printer_system_smf_state printer_system_smf_get_state();

#endif // PRINTER_SYSTEM_SMF_H
```

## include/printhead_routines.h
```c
#ifndef PRINTHEAD_ROUTINES_H
#define PRINTHEAD_ROUTINES_H

#include <zephyr/smf.h>
#include <zephyr/kernel.h>

typedef void (*printhead_routines_error_callback_t)(void);

typedef struct
{
    printhead_routines_error_callback_t error_callback;
} printhead_routines_init_t;

typedef struct
{
    uint32_t activated_period;
} printhead_routines_info_t;

enum printhead_routine_state
{
    PRINTHEAD_ROUTINE_ACTIVATE_ENABLE_CLOCK,
    PRINTHEAD_ROUTINE_ACTIVATE_ENABLE_VPP,
    PRINTHEAD_ROUTINE_ACTIVATE_ENABLE_VPP_PULSE,
    PRINTHEAD_ROUTINE_ACTIVATE_ENABLE_COMM_RESET,
    PRINTHEAD_ROUTINE_ACTIVATE_ENABLE_RESET_PULSE,
    PRINTHEAD_ROUTINE_SHUTDOWN_DISABLE_RESET,
    PRINTHEAD_ROUTINE_SHUTDOWN_DISABLE_VPP
};

#define PRINTHEAD_ROUTINE_ACTIVATE_INITIAL (PRINTHEAD_ROUTINE_ACTIVATE_ENABLE_CLOCK)
#define PRINTHEAD_ROUTINE_SHUTDOWN_INITIAL (PRINTHEAD_ROUTINE_SHUTDOWN_DISABLE_RESET)

int printhead_routine_smf(enum printhead_routine_state init_state);

int printhead_routines_initialize(printhead_routines_init_t *init);

void printhead_routines_go_to_safe_state();

int printhead_routines_config_period(uint32_t period);

void printhead_routines_get_info(printhead_routines_info_t *info);

#endif
```

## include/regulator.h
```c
#ifndef REGULATOR_H
#define REGULATOR_H

typedef struct
{
    bool voltage_reading_available;
    uint32_t voltage_mv;
    uint32_t set_voltage_mv;
} regulator_info_t;

int regulator_initialize(void);

bool regulator_get_voltage(uint32_t *voltage_mv);

int regulator_set_voltage(uint32_t voltage_mv);

void regulator_get_info(regulator_info_t *info);

#endif // REGULATOR_H
```

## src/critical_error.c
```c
#include <zephyr/drivers/gpio.h>

#include "pressure_control.h"
#include "printhead_routines.h"
#include "printer_system_smf.h"

static const struct gpio_dt_spec n_reset_mcu = GPIO_DT_SPEC_GET(DT_NODELABEL(n_reset_mcu), gpios);

void critical_error_handler(){
    gpio_pin_set(n_reset_mcu.port, n_reset_mcu.pin, 0);
    printer_system_smf_go_to_error();
    printhead_routine_cancel();
    pressure_control_enable(false);
}
```

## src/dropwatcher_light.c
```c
#include <stdint.h>
#include <zephyr/kernel.h>
#include <zephyr/device.h>
#include <zephyr/drivers/printer_fire.h>
#include <zephyr/logging/log.h>

#include "dropwatcher_light.h"

LOG_MODULE_REGISTER(dropwatcher_light, CONFIG_APP_LOG_LEVEL);

static const struct device *printer_fire_device = DEVICE_DT_GET(DT_NODELABEL(printer_fire));

int set_light_timing(uint32_t delay, uint32_t on_time) {
    if (!device_is_ready(printer_fire_device)) {
        return -ENODEV;
    }
    LOG_INF("Setting light timing: delay=%d, on_time=%d", delay, on_time);
    return printer_fire_set_light_timing(printer_fire_device, delay, on_time);
}
```

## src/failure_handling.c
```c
#include <stddef.h>
#include "failure_handling.h"
#include <zephyr/logging/log.h>

static volatile uint32_t error_state = 0;
static failure_callback_t failure_callback;


LOG_MODULE_REGISTER(failure_handling, CONFIG_APP_LOG_LEVEL);

bool failure_handling_is_in_error_state(void)
{
    return error_state != 0;
}

uint32_t failure_handling_get_error_state(void) {
    return error_state;
}

void failure_handling_set_error_state(uint32_t error)
{
    if (error_state == 0)
    {
        failure_callback();
    }
    error_state |= error;
    LOG_INF("Error state set %d", error);
}

int failure_handling_initialize(failure_handling_init_t *init) {
    if (init->failure_callback == NULL)
    {
        return -1;
    }
    failure_callback = init->failure_callback;
    return 0;
}
```
